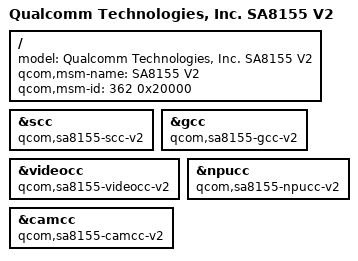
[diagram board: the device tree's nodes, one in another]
#include "sm8150-v2.dtsi"
#include "sa8155.dtsi"

/ {
	model = "Qualcomm Technologies, Inc. SA8155 V2";
	qcom,msm-name = "SA8155 V2";
	qcom,msm-id = <362 0x20000>;
};

&scc {
	compatible = "qcom,sa8155-scc-v2", "syscon";
};

&gcc {
	compatible = "qcom,sa8155-gcc-v2", "syscon";
};

&videocc {
	compatible = "qcom,sa8155-videocc-v2", "syscon";
};

&npucc {
	compatible = "qcom,sa8155-npucc-v2", "syscon";
};

&camcc {
	compatible = "qcom,sa8155-camcc-v2", "syscon";
};
